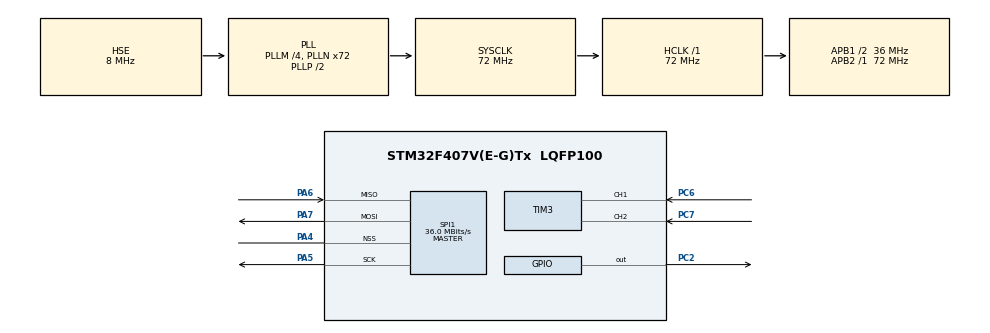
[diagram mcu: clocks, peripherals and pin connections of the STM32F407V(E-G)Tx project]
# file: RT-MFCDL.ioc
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Mcu.Family=STM32F4
Mcu.Name=STM32F407V(E-G)Tx
Mcu.Package=LQFP100
NVIC.PriorityGroup=NVIC_PRIORITYGROUP_4
PA4.Mode=NSS_Signal_Hard
PA4.Signal=SPI1_NSS
PA5.Mode=Full_Duplex_Master
PA5.Signal=SPI1_SCK
PA6.Mode=Full_Duplex_Master
PA6.Signal=SPI1_MISO
PA7.Mode=Full_Duplex_Master
PA7.Signal=SPI1_MOSI
PC14-OSC32_IN.Mode=LSE-External-Oscillator
PC14-OSC32_IN.Signal=RCC_OSC32_IN
PC15-OSC32_OUT.Mode=LSE-External-Oscillator
PC15-OSC32_OUT.Signal=RCC_OSC32_OUT
PC2.Signal=GPIO_Output
PC6.Signal=S_TIM3_CH1
PC7.Signal=S_TIM3_CH2
PH0-OSC_IN.Mode=HSE-External-Oscillator
PH0-OSC_IN.Signal=RCC_OSC_IN
PH1-OSC_OUT.Mode=HSE-External-Oscillator
PH1-OSC_OUT.Signal=RCC_OSC_OUT
ProjectManager.TargetToolchain=MDK-ARM V5
RCC.48MHZClocksFreq_Value=48000000
RCC.AHBFreq_Value=72000000
RCC.APB1CLKDivider=RCC_HCLK_DIV2
RCC.APB1Freq_Value=36000000
RCC.APB1TimFreq_Value=72000000
RCC.APB2Freq_Value=72000000
RCC.APB2TimFreq_Value=72000000
RCC.CortexFreq_Value=72000000
RCC.HCLKFreq_Value=72000000
RCC.HSE_VALUE=8000000
RCC.HSI_VALUE=16000000
RCC.PLLM=4
RCC.PLLN=72
RCC.PLLQ=3
RCC.PLLSourceVirtual=RCC_PLLSOURCE_HSE
RCC.SYSCLKFreq_VALUE=72000000
RCC.SYSCLKSource=RCC_SYSCLKSOURCE_PLLCLK
RCC.VCOOutputFreq_Value=144000000
SH.S_TIM3_CH1.0=TIM3_CH1,Encoder_Interface
SH.S_TIM3_CH2.0=TIM3_CH2,Encoder_Interface
SPI1.CalculateBaudRate=36.0 MBits/s
SPI1.Mode=SPI_MODE_MASTER
SPI1.VirtualNSS=VM_NSSHARD
board=RT-MFCDL

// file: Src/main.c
/**
  ******************************************************************************
  * File Name          : main.c
  * Description        : Main program body
  ******************************************************************************
  *
  * COPYRIGHT(c) 2016 STMicroelectronics
  *
  * Redistribution and use in source and binary forms, with or without modification,
  * are permitted provided that the following conditions are met:
  *   1. Redistributions of source code must retain the above copyright notice,
  *      this list of conditions and the following disclaimer.
  *   2. Redistributions in binary form must reproduce the above copyright notice,
  *      this list of conditions and the following disclaimer in the documentation
  *      and/or other materials provided with the distribution.
  *   3. Neither the name of STMicroelectronics nor the names of its contributors
  *      may be used to endorse or promote products derived from this software
  *      without specific prior written permission.
  *
  * THIS SOFTWARE IS PROVIDED BY THE COPYRIGHT HOLDERS AND CONTRIBUTORS "AS IS"
  * AND ANY EXPRESS OR IMPLIED WARRANTIES, INCLUDING, BUT NOT LIMITED TO, THE
  * IMPLIED WARRANTIES OF MERCHANTABILITY AND FITNESS FOR A PARTICULAR PURPOSE ARE
  * DISCLAIMED. IN NO EVENT SHALL THE COPYRIGHT HOLDER OR CONTRIBUTORS BE LIABLE
  * FOR ANY DIRECT, INDIRECT, INCIDENTAL, SPECIAL, EXEMPLARY, OR CONSEQUENTIAL
  * DAMAGES (INCLUDING, BUT NOT LIMITED TO, PROCUREMENT OF SUBSTITUTE GOODS OR
  * SERVICES; LOSS OF USE, DATA, OR PROFITS; OR BUSINESS INTERRUPTION) HOWEVER
  * CAUSED AND ON ANY THEORY OF LIABILITY, WHETHER IN CONTRACT, STRICT LIABILITY,
  * OR TORT (INCLUDING NEGLIGENCE OR OTHERWISE) ARISING IN ANY WAY OUT OF THE USE
  * OF THIS SOFTWARE, EVEN IF ADVISED OF THE POSSIBILITY OF SUCH DAMAGE.
  *
  ******************************************************************************
  */
#include "stm32f4xx_hal.h"
#include "spi.h"
#include "tim.h"
#include "gpio.h"

/* USER CODE BEGIN PV */
/* Private variables ---------------------------------------------------------*/
int32_t encoderTicks;
int32_t dir;
/* USER CODE END PV */

void SystemClock_Config(void);

/* USER CODE BEGIN PFP */
/* Private function prototypes -----------------------------------------------*/

/* USER CODE END PFP */

int main(void)
{

  /* MCU Configuration----------------------------------------------------------*/

  /* Reset of all peripherals, Initializes the Flash interface and the Systick. */
  HAL_Init();

  /* Configure the system clock */
  SystemClock_Config();

  /* Initialize all configured peripherals */
  MX_GPIO_Init();
  MX_SPI1_Init();
  MX_TIM3_Init();

  /* USER CODE BEGIN 2 */

	HAL_TIM_Encoder_Start(&htim3, TIM_CHANNEL_ALL);

  /* USER CODE END 2 */

  /* Infinite loop */
  /* USER CODE BEGIN WHILE */
	encoderTicks=0;
	dir=0;
  while (1)
  {
//		HAL_GPIO_TogglePin(GPIOC,GPIO_PIN_2);
//		HAL_Delay(1);
//		__HAL_TIM_SET_COUNTER(&htim3,encoderTicks);
		encoderTicks =__HAL_TIM_GET_COUNTER(&htim3);
  /* USER CODE END WHILE */

  }

}

/** System Clock Configuration
*/
void SystemClock_Config(void)
{

  RCC_OscInitTypeDef RCC_OscInitStruct;
  RCC_ClkInitTypeDef RCC_ClkInitStruct;

  __PWR_CLK_ENABLE();

  __HAL_PWR_VOLTAGESCALING_CONFIG(PWR_REGULATOR_VOLTAGE_SCALE1);

  RCC_OscInitStruct.OscillatorType = RCC_OSCILLATORTYPE_HSE;
  RCC_OscInitStruct.HSEState = RCC_HSE_ON;
  RCC_OscInitStruct.PLL.PLLState = RCC_PLL_ON;
  RCC_OscInitStruct.PLL.PLLSource = RCC_PLLSOURCE_HSE;
  RCC_OscInitStruct.PLL.PLLM = 4;
  RCC_OscInitStruct.PLL.PLLN = 72;
  RCC_OscInitStruct.PLL.PLLP = RCC_PLLP_DIV2;
  RCC_OscInitStruct.PLL.PLLQ = 3;
  HAL_RCC_OscConfig(&RCC_OscInitStruct);

  RCC_ClkInitStruct.ClockType = RCC_CLOCKTYPE_SYSCLK|RCC_CLOCKTYPE_PCLK1;
  RCC_ClkInitStruct.SYSCLKSource = RCC_SYSCLKSOURCE_PLLCLK;
  RCC_ClkInitStruct.AHBCLKDivider = RCC_SYSCLK_DIV1;
  RCC_ClkInitStruct.APB1CLKDivider = RCC_HCLK_DIV2;
  RCC_ClkInitStruct.APB2CLKDivider = RCC_HCLK_DIV1;
  HAL_RCC_ClockConfig(&RCC_ClkInitStruct, FLASH_LATENCY_2);

  HAL_SYSTICK_Config(HAL_RCC_GetHCLKFreq()/1000);

  HAL_SYSTICK_CLKSourceConfig(SYSTICK_CLKSOURCE_HCLK);

  /* SysTick_IRQn interrupt configuration */
  HAL_NVIC_SetPriority(SysTick_IRQn, 0, 0);
}

/************************ (C) COPYRIGHT STMicroelectronics *****END OF FILE****/
